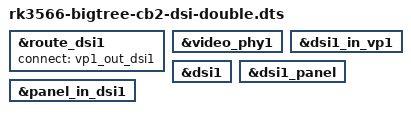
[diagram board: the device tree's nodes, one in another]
/dts-v1/;
/plugin/;

/ {
	
	fragment@0 {
		target = <&route_dsi1>;

		__overlay__ {
			
			status = "okay";
			connect = <&vp1_out_dsi1>;		
		};
	};
	
	fragment@1 {
		target = <&video_phy1>;

		__overlay__ {
			
			status = "okay";			
		};
	};
	
	fragment@2 {
		target = <&dsi1_in_vp1>;

		__overlay__ {
			
			status = "okay";	
		};
	};
		
	fragment@3 {
		target = <&dsi1>;

		__overlay__ {
			
			status = "okay";			
		};
	};
	
	fragment@4 {
		target = <&dsi1_panel>;

		__overlay__ {
			
			status = "okay";			
		};
	};
	
	fragment@5 {
		target = <&panel_in_dsi1>;

		__overlay__ {
			
			status = "okay";			
		};
	};
		
};
